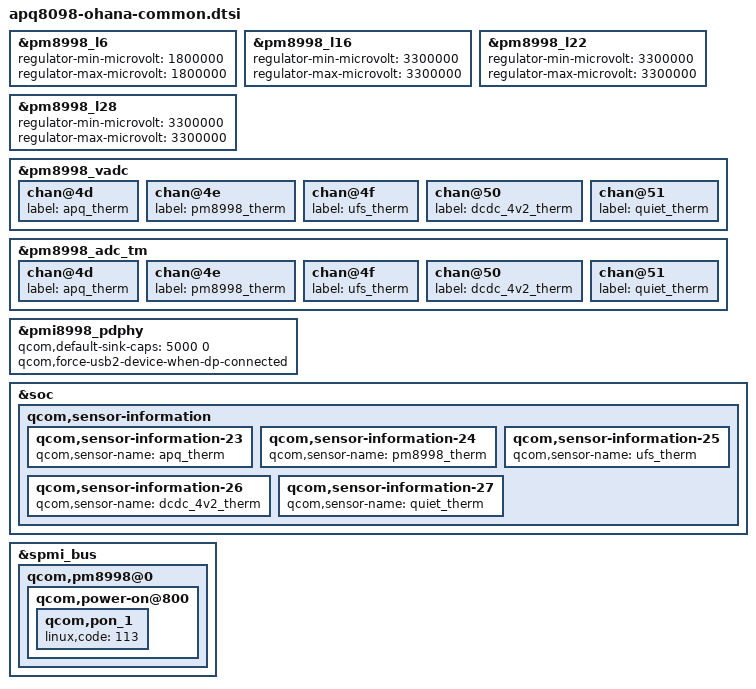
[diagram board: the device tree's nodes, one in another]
/* Copyright (c) 2017, Facebook Inc. All rights reserved.
 *
 * This program is free software; you can redistribute it and/or modify
 * it under the terms of the GNU General Public License version 2 and
 * only version 2 as published by the Free Software Foundation.
 *
 * This program is distributed in the hope that it will be useful,
 * but WITHOUT ANY WARRANTY; without even the implied warranty of
 * MERCHANTABILITY or FITNESS FOR A PARTICULAR PURPOSE.  See the
 * GNU General Public License for more details.
 */

&pm8998_l6 {
	regulator-min-microvolt = <1800000>;
	regulator-max-microvolt = <1800000>;
};

&pm8998_l16 {
	regulator-min-microvolt = <3300000>;
	regulator-max-microvolt = <3300000>;
};

&pm8998_l22 {
	regulator-min-microvolt = <3300000>;
	regulator-max-microvolt = <3300000>;
};

&pm8998_l28 {
	regulator-min-microvolt = <3300000>;
	regulator-max-microvolt = <3300000>;
};

&pm8998_vadc {
	chan@4d {
		label = "apq_therm";
	};

	chan@4e {
		label = "pm8998_therm";
	};

	chan@4f {
		label = "ufs_therm";
	};

	chan@50 {
		label = "dcdc_4v2_therm";
	};

	chan@51 {
		label = "quiet_therm";
	};
};

&pm8998_adc_tm {
	chan@4d {
		label = "apq_therm";
	};

	chan@4e {
		label = "pm8998_therm";
	};

	chan@4f {
		label = "ufs_therm";
	};

	chan@50 {
		label = "dcdc_4v2_therm";
	};

	chan@51 {
		label = "quiet_therm";
	};
};

&pmi8998_pdphy {
	qcom,default-sink-caps = <5000 0>; /* 5V @ 0A */
	qcom,force-usb2-device-when-dp-connected;
};

&soc {
	qcom,sensor-information {
		qcom,sensor-information-23 {
			qcom,sensor-name = "apq_therm";
		};

		qcom,sensor-information-24 {
			qcom,sensor-name = "pm8998_therm";
		};

		qcom,sensor-information-25 {
			qcom,sensor-name = "ufs_therm";
		};

		qcom,sensor-information-26 {
			qcom,sensor-name = "dcdc_4v2_therm";
		};

		qcom,sensor-information-27 {
			qcom,sensor-name = "quiet_therm";
		};
	};
};

&spmi_bus {
	qcom,pm8998@0 {
		qcom,power-on@800 {
			qcom,pon_1 {
				linux,code = <113>;
			};
		};
	};
};
